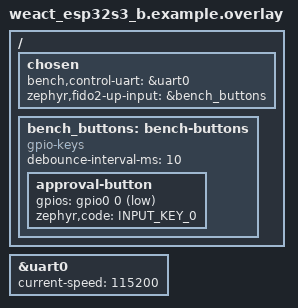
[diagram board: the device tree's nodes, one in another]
/*
 * Physical UART control profile: GPIO0 presence button, USB CTAP, UART0 control.
 */
#include <zephyr/dt-bindings/gpio/gpio.h>
#include <zephyr/dt-bindings/input/input-event-codes.h>

/ {
	chosen {
		bench,control-uart = &uart0;
		zephyr,fido2-up-input = &bench_buttons;
	};

	bench_buttons: bench-buttons {
		compatible = "gpio-keys";
		debounce-interval-ms = <10>;
		approval-button {
			gpios = <&gpio0 0 (GPIO_PULL_UP | GPIO_ACTIVE_LOW)>;
			zephyr,code = <INPUT_KEY_0>;
		};
	};
};

&uart0 {
	status = "okay";
	current-speed = <115200>;
};
